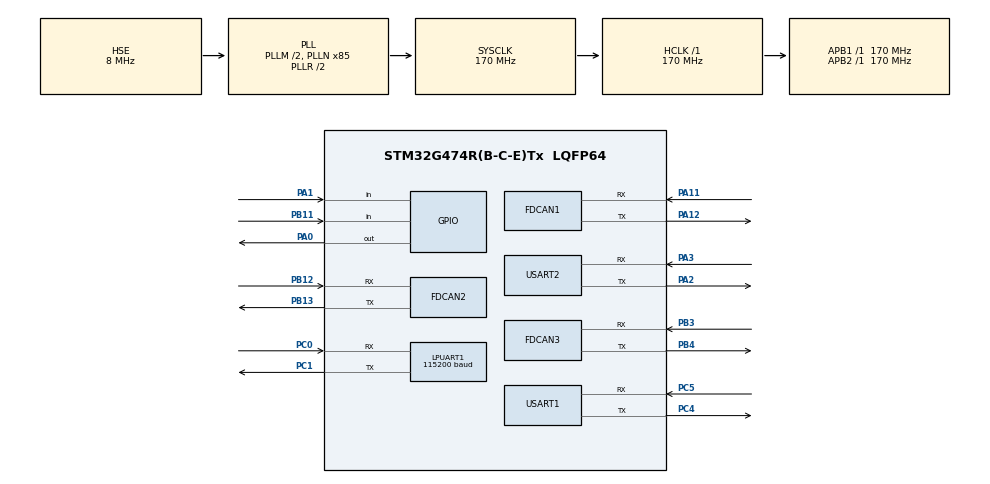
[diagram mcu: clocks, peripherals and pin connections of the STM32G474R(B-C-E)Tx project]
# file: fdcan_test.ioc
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Dma.Request0=USART2_TX
Dma.Request1=USART2_RX
Dma.USART2_RX.1.Direction=DMA_PERIPH_TO_MEMORY
Dma.USART2_RX.1.EventEnable=DISABLE
Dma.USART2_RX.1.Instance=DMA1_Channel1
Dma.USART2_RX.1.MemDataAlignment=DMA_MDATAALIGN_BYTE
Dma.USART2_RX.1.MemInc=DMA_MINC_ENABLE
Dma.USART2_RX.1.Mode=DMA_NORMAL
Dma.USART2_RX.1.PeriphDataAlignment=DMA_PDATAALIGN_BYTE
Dma.USART2_RX.1.PeriphInc=DMA_PINC_DISABLE
Dma.USART2_RX.1.Polarity=HAL_DMAMUX_REQ_GEN_RISING
Dma.USART2_RX.1.Priority=DMA_PRIORITY_LOW
Dma.USART2_RX.1.RequestNumber=1
Dma.USART2_RX.1.SignalID=NONE
Dma.USART2_RX.1.SyncEnable=DISABLE
Dma.USART2_RX.1.SyncPolarity=HAL_DMAMUX_SYNC_NO_EVENT
Dma.USART2_RX.1.SyncRequestNumber=1
Dma.USART2_RX.1.SyncSignalID=NONE
Dma.USART2_TX.0.Direction=DMA_MEMORY_TO_PERIPH
Dma.USART2_TX.0.EventEnable=DISABLE
Dma.USART2_TX.0.Instance=DMA1_Channel2
Dma.USART2_TX.0.MemDataAlignment=DMA_MDATAALIGN_BYTE
Dma.USART2_TX.0.MemInc=DMA_MINC_ENABLE
Dma.USART2_TX.0.Mode=DMA_NORMAL
Dma.USART2_TX.0.PeriphDataAlignment=DMA_PDATAALIGN_BYTE
Dma.USART2_TX.0.PeriphInc=DMA_PINC_DISABLE
Dma.USART2_TX.0.Polarity=HAL_DMAMUX_REQ_GEN_RISING
Dma.USART2_TX.0.Priority=DMA_PRIORITY_LOW
Dma.USART2_TX.0.RequestNumber=1
Dma.USART2_TX.0.SignalID=NONE
Dma.USART2_TX.0.SyncEnable=DISABLE
Dma.USART2_TX.0.SyncPolarity=HAL_DMAMUX_SYNC_NO_EVENT
Dma.USART2_TX.0.SyncRequestNumber=1
Dma.USART2_TX.0.SyncSignalID=NONE
FDCAN1.AutoRetransmission=ENABLE
FDCAN1.CalculateBaudRateNominal=1000000
FDCAN1.CalculateTimeBitNominal=1000
FDCAN1.CalculateTimeQuantumNominal=100.0
FDCAN1.DataPrescaler=17
FDCAN1.DataTimeSeg1=8
FDCAN1.DataTimeSeg2=3
FDCAN1.FrameFormat=FDCAN_FRAME_FD_NO_BRS
FDCAN1.NominalPrescaler=17
FDCAN1.NominalTimeSeg1=6
FDCAN1.NominalTimeSeg2=3
FDCAN2.AutoRetransmission=ENABLE
FDCAN2.CalculateBaudRateNominal=1000000
FDCAN2.CalculateTimeBitNominal=1000
FDCAN2.CalculateTimeQuantumNominal=100.0
FDCAN2.DataPrescaler=17
FDCAN2.DataTimeSeg1=8
FDCAN2.DataTimeSeg2=3
FDCAN2.NominalPrescaler=17
FDCAN2.NominalTimeSeg1=6
FDCAN2.NominalTimeSeg2=3
FDCAN3.AutoRetransmission=ENABLE
FDCAN3.CalculateBaudRateNominal=1000000
FDCAN3.CalculateTimeBitNominal=1000
FDCAN3.CalculateTimeQuantumNominal=100.0
FDCAN3.DataPrescaler=17
FDCAN3.DataTimeSeg1=8
FDCAN3.DataTimeSeg2=3
FDCAN3.NominalPrescaler=17
FDCAN3.NominalTimeSeg1=6
FDCAN3.NominalTimeSeg2=3
FREERTOS.INCLUDE_pcTaskGetTaskName=1
FREERTOS.INCLUDE_uxTaskGetStackHighWaterMark2=1
FREERTOS.INCLUDE_vTaskCleanUpResources=1
FREERTOS.INCLUDE_xEventGroupSetBitFromISR=1
FREERTOS.INCLUDE_xSemaphoreGetMutexHolder=1
FREERTOS.INCLUDE_xTaskAbortDelay=1
FREERTOS.INCLUDE_xTaskGetHandle=1
FREERTOS.Tasks01=defaultTask,24,256,StartDefaultTask,Default,NULL,Dynamic,NULL,NULL;myTask02,8,256,StartTask02,As weak,NULL,Dynamic,NULL,NULL;myTask03,8,256,StartTask03,Default,NULL,Dynamic,NULL,NULL;myTask04,8,256,StartTask04,Default,NULL,Dynamic,NULL,NULL;myTask05,8,256,StartTask05,Default,NULL,Dynamic,NULL,NULL
FREERTOS.configMINIMAL_STACK_SIZE=256
FREERTOS.configTOTAL_HEAP_SIZE=6144
LPUART1.BaudRate=115200
Mcu.Family=STM32G4
Mcu.Name=STM32G474R(B-C-E)Tx
Mcu.Package=LQFP64
NVIC.DMA1_Channel1_IRQn=true\:5\:0\:false\:false\:true\:true\:false\:true\:true
NVIC.DMA1_Channel2_IRQn=true\:5\:0\:false\:false\:true\:true\:false\:true\:true
NVIC.FDCAN1_IT0_IRQn=true\:5\:0\:false\:false\:true\:true\:true\:true\:true
NVIC.FDCAN1_IT1_IRQn=true\:5\:0\:false\:false\:true\:true\:true\:true\:true
NVIC.FDCAN2_IT0_IRQn=true\:5\:0\:false\:false\:true\:true\:true\:true\:true
NVIC.FDCAN2_IT1_IRQn=true\:5\:0\:false\:false\:true\:true\:true\:true\:true
NVIC.FDCAN3_IT0_IRQn=true\:5\:0\:false\:false\:true\:true\:true\:true\:true
NVIC.FDCAN3_IT1_IRQn=true\:5\:0\:false\:false\:true\:true\:true\:true\:true
NVIC.LPUART1_IRQn=true\:5\:0\:false\:false\:true\:true\:true\:true\:true
NVIC.PriorityGroup=NVIC_PRIORITYGROUP_4
NVIC.TIM4_IRQn=true\:15\:0\:false\:false\:true\:false\:false\:true\:true
NVIC.TimeBase=TIM4_IRQn
NVIC.TimeBaseIP=TIM4
NVIC.USART1_IRQn=true\:5\:0\:false\:false\:true\:true\:true\:true\:true
NVIC.USART2_IRQn=true\:5\:0\:false\:false\:true\:true\:true\:true\:true
PA0.GPIO_PuPd=GPIO_PULLUP
PA0.PinState=GPIO_PIN_RESET
PA0.Signal=GPIO_Output
PA1.Signal=GPIO_Input
PA11.Mode=FDCAN_Activate
PA11.Signal=FDCAN1_RX
PA12.Mode=FDCAN_Activate
PA12.Signal=FDCAN1_TX
PA13.Mode=Serial_Wire
PA13.Signal=SYS_JTMS-SWDIO
PA14.Mode=Serial_Wire
PA14.Signal=SYS_JTCK-SWCLK
PA2.Mode=Asynchronous
PA2.Signal=USART2_TX
PA3.Mode=Asynchronous
PA3.Signal=USART2_RX
PB11.GPIO_PuPd=GPIO_PULLUP
PB11.Signal=GPIO_Input
PB12.Mode=FDCAN_Activate
PB12.Signal=FDCAN2_RX
PB13.Mode=FDCAN_Activate
PB13.Signal=FDCAN2_TX
PB3.Mode=FDCAN_Activate
PB3.Signal=FDCAN3_RX
PB4.Mode=FDCAN_Activate
PB4.Signal=FDCAN3_TX
PC0.Mode=Asynchronous
PC0.Signal=LPUART1_RX
PC1.Mode=Asynchronous
PC1.Signal=LPUART1_TX
PC4.Mode=Asynchronous
PC4.Signal=USART1_TX
PC5.Mode=Asynchronous
PC5.Signal=USART1_RX
PF0-OSC_IN.Mode=HSE-External-Oscillator
PF0-OSC_IN.Signal=RCC_OSC_IN
PF1-OSC_OUT.Mode=HSE-External-Oscillator
PF1-OSC_OUT.Signal=RCC_OSC_OUT
ProjectManager.HeapSize=0x200
ProjectManager.StackSize=0x400
ProjectManager.TargetToolchain=MDK-ARM V5.32
RCC.ADC12Freq_Value=170000000
RCC.ADC345Freq_Value=170000000
RCC.AHBFreq_Value=170000000
RCC.APB1Freq_Value=170000000
RCC.APB1TimFreq_Value=170000000
RCC.APB2Freq_Value=170000000
RCC.APB2TimFreq_Value=170000000
RCC.CortexFreq_Value=170000000
RCC.EXTERNAL_CLOCK_VALUE=12288000
RCC.HCLKFreq_Value=170000000
RCC.HSE_VALUE=8000000
RCC.HSI48_VALUE=48000000
RCC.HSI_VALUE=16000000
RCC.LSE_VALUE=32768
RCC.PLLM=RCC_PLLM_DIV2
RCC.PLLN=85
RCC.PLLSourceVirtual=RCC_PLLSOURCE_HSE
RCC.SYSCLKFreq_VALUE=170000000
RCC.SYSCLKSource=RCC_SYSCLKSOURCE_PLLCLK
RCC.USBFreq_Value=170000000
RCC.VCOOutputFreq_Value=340000000
USART1.FIFOMode=FIFOMODE_DISABLE
USART1.VirtualMode-Asynchronous=VM_ASYNC
USART2.VirtualMode-Asynchronous=VM_ASYNC
VP_FREERTOS_VS_CMSIS_V2.Mode=CMSIS_V2
VP_SYS_VS_DBSignals.Mode=DisableDeadBatterySignals
VP_SYS_VS_tim4.Mode=TIM4
board=custom

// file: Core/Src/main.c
/* USER CODE BEGIN Header */
/**
  ******************************************************************************
  * @file           : main.c
  * @brief          : Main program body
  ******************************************************************************
  * @attention
  *
  * Copyright (c) 2025 STMicroelectronics.
  * All rights reserved.
  *
  * This software is licensed under terms that can be found in the LICENSE file
  * in the root directory of this software component.
  * If no LICENSE file comes with this software, it is provided AS-IS.
  *
  ******************************************************************************
  */
/* USER CODE END Header */
#include "main.h"
#include "cmsis_os.h"
#include "dma.h"
#include "fdcan.h"
#include "usart.h"
#include "gpio.h"

/* USER CODE BEGIN Includes */
#include "stdio.h"
#include "string.h"
#include "fdcan_bsp.h"
#include "robot_data.h"
#include "chassis_task.h"
int fputc(int ch, FILE *f) {
HAL_UART_Transmit(&hlpuart1, (uint8_t *)&ch, 1, 0xffff);
return ch;
}
/* USER CODE END Includes */

void SystemClock_Config(void);
void MX_FREERTOS_Init(void);

int main(void)
{

  /* MCU Configuration--------------------------------------------------------*/

  /* Reset of all peripherals, Initializes the Flash interface and the Systick. */
  HAL_Init();

  /* Configure the system clock */
  SystemClock_Config();

  /* Initialize all configured peripherals */
  MX_GPIO_Init();
  MX_DMA_Init();
  MX_FDCAN1_Init();
  MX_USART1_UART_Init();
  MX_FDCAN3_Init();
  MX_FDCAN2_Init();
  MX_USART2_UART_Init();
  MX_LPUART1_UART_Init();
  /* USER CODE BEGIN 2 */

	printf("FDCAN System Started!\r\n");
  /* USER CODE END 2 */

  /* Init scheduler */
  osKernelInitialize();  /* Call init function for freertos objects (in cmsis_os2.c) */
  MX_FREERTOS_Init();

  /* Start scheduler */
  osKernelStart();

  /* We should never get here as control is now taken by the scheduler */

  /* Infinite loop */
  while (1)
  {

  }
}

void SystemClock_Config(void)
{
  RCC_OscInitTypeDef RCC_OscInitStruct = {0};
  RCC_ClkInitTypeDef RCC_ClkInitStruct = {0};

  /** Configure the main internal regulator output voltage
  */
  HAL_PWREx_ControlVoltageScaling(PWR_REGULATOR_VOLTAGE_SCALE1_BOOST);

  /** Initializes the RCC Oscillators according to the specified parameters
  * in the RCC_OscInitTypeDef structure.
  */
  RCC_OscInitStruct.OscillatorType = RCC_OSCILLATORTYPE_HSE;
  RCC_OscInitStruct.HSEState = RCC_HSE_ON;
  RCC_OscInitStruct.PLL.PLLState = RCC_PLL_ON;
  RCC_OscInitStruct.PLL.PLLSource = RCC_PLLSOURCE_HSE;
  RCC_OscInitStruct.PLL.PLLM = RCC_PLLM_DIV2;
  RCC_OscInitStruct.PLL.PLLN = 85;
  RCC_OscInitStruct.PLL.PLLP = RCC_PLLP_DIV2;
  RCC_OscInitStruct.PLL.PLLQ = RCC_PLLQ_DIV2;
  RCC_OscInitStruct.PLL.PLLR = RCC_PLLR_DIV2;
  if (HAL_RCC_OscConfig(&RCC_OscInitStruct) != HAL_OK)
  {
    Error_Handler();
  }

  /** Initializes the CPU, AHB and APB buses clocks
  */
  RCC_ClkInitStruct.ClockType = RCC_CLOCKTYPE_HCLK|RCC_CLOCKTYPE_SYSCLK
                              |RCC_CLOCKTYPE_PCLK1|RCC_CLOCKTYPE_PCLK2;
  RCC_ClkInitStruct.SYSCLKSource = RCC_SYSCLKSOURCE_PLLCLK;
  RCC_ClkInitStruct.AHBCLKDivider = RCC_SYSCLK_DIV1;
  RCC_ClkInitStruct.APB1CLKDivider = RCC_HCLK_DIV1;
  RCC_ClkInitStruct.APB2CLKDivider = RCC_HCLK_DIV1;

  if (HAL_RCC_ClockConfig(&RCC_ClkInitStruct, FLASH_LATENCY_4) != HAL_OK)
  {
    Error_Handler();
  }
}

void HAL_TIM_PeriodElapsedCallback(TIM_HandleTypeDef *htim)
{
  if (htim->Instance == TIM4)
  {
    HAL_IncTick();
  }
}

void Error_Handler(void)
{
  __disable_irq();
  while (1)
  {
  }
}
